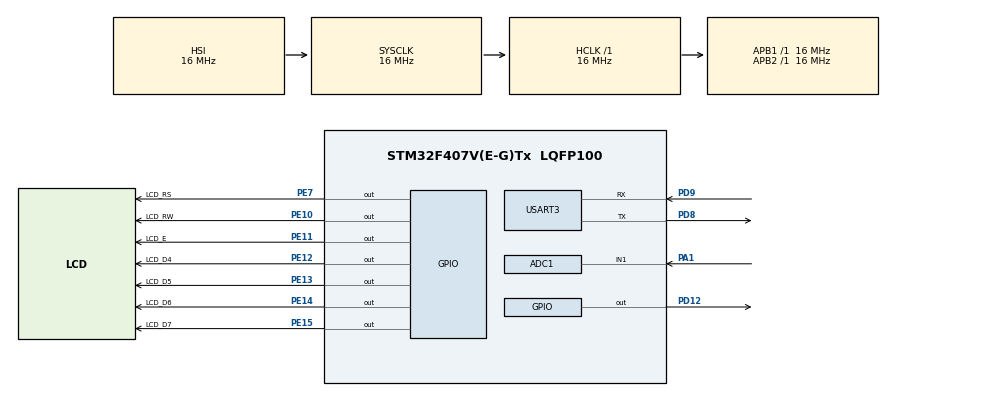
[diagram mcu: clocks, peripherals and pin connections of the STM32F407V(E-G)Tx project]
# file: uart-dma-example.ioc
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ADC1.Channel-1\#ChannelRegularConversion=ADC_CHANNEL_1
ADC1.NbrOfConversionFlag=1
ADC1.Rank-1\#ChannelRegularConversion=1
ADC1.SamplingTime-1\#ChannelRegularConversion=ADC_SAMPLETIME_3CYCLES
ADC1.master=1
Dma.Request0=USART3_RX
Dma.USART3_RX.0.Direction=DMA_PERIPH_TO_MEMORY
Dma.USART3_RX.0.FIFOMode=DMA_FIFOMODE_DISABLE
Dma.USART3_RX.0.Instance=DMA1_Stream1
Dma.USART3_RX.0.MemDataAlignment=DMA_MDATAALIGN_BYTE
Dma.USART3_RX.0.MemInc=DMA_MINC_ENABLE
Dma.USART3_RX.0.Mode=DMA_CIRCULAR
Dma.USART3_RX.0.PeriphDataAlignment=DMA_PDATAALIGN_BYTE
Dma.USART3_RX.0.PeriphInc=DMA_PINC_DISABLE
Dma.USART3_RX.0.Priority=DMA_PRIORITY_LOW
FREERTOS.Tasks01=serial_listener,24,128,serial_listen,Default,NULL,Dynamic,NULL,NULL;display_task,24,128,lcd_display,Default,NULL,Dynamic,NULL,NULL
Mcu.Family=STM32F4
Mcu.Name=STM32F407V(E-G)Tx
Mcu.Package=LQFP100
NVIC.DMA1_Stream1_IRQn=true\:5\:0\:false\:false\:true\:true\:false\:true
NVIC.PriorityGroup=NVIC_PRIORITYGROUP_4
NVIC.TIM6_DAC_IRQn=true\:15\:0\:false\:false\:true\:false\:false\:true
NVIC.TimeBase=TIM6_DAC_IRQn
NVIC.TimeBaseIP=TIM6
PA1.Signal=ADCx_IN1
PD12.Signal=GPIO_Output
PD8.Mode=Asynchronous
PD8.Signal=USART3_TX
PD9.Mode=Asynchronous
PD9.Signal=USART3_RX
PE10.GPIO_Label=LCD_RW
PE10.Signal=GPIO_Output
PE11.GPIO_Label=LCD_E
PE11.Signal=GPIO_Output
PE12.GPIO_Label=LCD_D4
PE12.Signal=GPIO_Output
PE13.GPIO_Label=LCD_D5
PE13.Signal=GPIO_Output
PE14.GPIO_Label=LCD_D6
PE14.Signal=GPIO_Output
PE15.GPIO_Label=LCD_D7
PE15.Signal=GPIO_Output
PE7.GPIO_Label=LCD_RS
PE7.Signal=GPIO_Output
ProjectManager.HeapSize=0x200
ProjectManager.StackSize=0x400
ProjectManager.TargetToolchain=STM32CubeIDE
RCC.AHBFreq_Value=16000000
RCC.APB1Freq_Value=16000000
RCC.APB2Freq_Value=16000000
RCC.CortexFreq_Value=16000000
RCC.HSE_VALUE=25000000
RCC.HSI_VALUE=16000000
RCC.LSE_VALUE=32768
RCC.SYSCLKFreq_VALUE=16000000
RCC.VCOOutputFreq_Value=192000000
SH.ADCx_IN1.0=ADC1_IN1,IN1
USART3.VirtualMode=VM_ASYNC
VP_FREERTOS_VS_CMSIS_V2.Mode=CMSIS_V2
VP_SYS_VS_tim6.Mode=TIM6
board=custom

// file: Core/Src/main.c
/* USER CODE BEGIN Header */
/**
 ******************************************************************************
 * @file           : main.c
 * @brief          : Main program body
 ******************************************************************************
 * @attention
 *
 * <h2><center>&copy; Copyright (c) 2021 STMicroelectronics.
 * All rights reserved.</center></h2>
 *
 * This software component is licensed by ST under BSD 3-Clause license,
 * the "License"; You may not use this file except in compliance with the
 * License. You may obtain a copy of the License at:
 *                        opensource.org/licenses/BSD-3-Clause
 *
 ******************************************************************************
 */
/* USER CODE END Header */
#include "main.h"
#include "cmsis_os.h"

/* USER CODE BEGIN Includes */
#include "hd44780.h"
#include "serial_listener.h"
#include "commands_manager.h"
/* USER CODE END Includes */

ADC_HandleTypeDef hadc1;

UART_HandleTypeDef huart3;
DMA_HandleTypeDef hdma_usart3_rx;

/* Definitions for serial_listener */
osThreadId_t serial_listenerHandle;
const osThreadAttr_t serial_listener_attributes = {
    .name = "serial_listener",
    .stack_size = 128 * 4,
    .priority = (osPriority_t) osPriorityNormal,
};
/* Definitions for display_task */
osThreadId_t display_taskHandle;
const osThreadAttr_t display_task_attributes = {
    .name = "display_task",
    .stack_size = 128 * 4,
    .priority = (osPriority_t) osPriorityNormal,
};

void SystemClock_Config(void);
static void MX_GPIO_Init(void);
static void MX_ADC1_Init(void);
static void MX_DMA_Init(void);
static void MX_USART3_UART_Init(void);
void serial_listen(void *argument);
void lcd_display(void *argument);

int main(void)
{

    /* MCU Configuration--------------------------------------------------------*/

    /* Reset of all peripherals, Initializes the Flash interface and the Systick. */
    HAL_Init();

    /* Configure the system clock */
    SystemClock_Config();

    /* Initialize all configured peripherals */
    MX_GPIO_Init();
    MX_ADC1_Init();
    MX_DMA_Init();
    MX_USART3_UART_Init();
    /* USER CODE BEGIN 2 */

    lcdInit();
    /* USER CODE END 2 */

    /* Init scheduler */
    osKernelInitialize();

    /* Create the thread(s) */
    /* creation of serial_listener */
    serial_listenerHandle = osThreadNew(serial_listen, NULL, &serial_listener_attributes);

    /* creation of display_task */
    display_taskHandle = osThreadNew(lcd_display, NULL, &display_task_attributes);

    /* Start scheduler */
    osKernelStart();

    /* We should never get here as control is now taken by the scheduler */
    /* Infinite loop */
    /* USER CODE BEGIN WHILE */

    //  while (1)
    //  {
    /* USER CODE END WHILE */

    /* USER CODE BEGIN 3 */
    //  }
    /* USER CODE END 3 */
}

void SystemClock_Config(void)
{
    RCC_OscInitTypeDef RCC_OscInitStruct = { 0 };
    RCC_ClkInitTypeDef RCC_ClkInitStruct = { 0 };

    /** Configure the main internal regulator output voltage
     */
    __HAL_RCC_PWR_CLK_ENABLE();
    __HAL_PWR_VOLTAGESCALING_CONFIG(PWR_REGULATOR_VOLTAGE_SCALE1);
    /** Initializes the RCC Oscillators according to the specified parameters
     * in the RCC_OscInitTypeDef structure.
     */
    RCC_OscInitStruct.OscillatorType = RCC_OSCILLATORTYPE_HSI;
    RCC_OscInitStruct.HSIState = RCC_HSI_ON;
    RCC_OscInitStruct.HSICalibrationValue = RCC_HSICALIBRATION_DEFAULT;
    RCC_OscInitStruct.PLL.PLLState = RCC_PLL_NONE;
    if (HAL_RCC_OscConfig(&RCC_OscInitStruct) != HAL_OK) {
        Error_Handler();
    }
    /** Initializes the CPU, AHB and APB buses clocks
     */
    RCC_ClkInitStruct.ClockType = RCC_CLOCKTYPE_HCLK | RCC_CLOCKTYPE_SYSCLK | RCC_CLOCKTYPE_PCLK1
            | RCC_CLOCKTYPE_PCLK2;
    RCC_ClkInitStruct.SYSCLKSource = RCC_SYSCLKSOURCE_HSI;
    RCC_ClkInitStruct.AHBCLKDivider = RCC_SYSCLK_DIV1;
    RCC_ClkInitStruct.APB1CLKDivider = RCC_HCLK_DIV1;
    RCC_ClkInitStruct.APB2CLKDivider = RCC_HCLK_DIV1;

    if (HAL_RCC_ClockConfig(&RCC_ClkInitStruct, FLASH_LATENCY_0) != HAL_OK) {
        Error_Handler();
    }
}

static void MX_ADC1_Init(void)
{

    ADC_ChannelConfTypeDef sConfig = { 0 };

    /** Configure the global features of the ADC (Clock, Resolution, Data Alignment and number of conversion)
     */
    hadc1.Instance = ADC1;
    hadc1.Init.ClockPrescaler = ADC_CLOCK_SYNC_PCLK_DIV2;
    hadc1.Init.Resolution = ADC_RESOLUTION_12B;
    hadc1.Init.ScanConvMode = DISABLE;
    hadc1.Init.ContinuousConvMode = DISABLE;
    hadc1.Init.DiscontinuousConvMode = DISABLE;
    hadc1.Init.ExternalTrigConvEdge = ADC_EXTERNALTRIGCONVEDGE_NONE;
    hadc1.Init.ExternalTrigConv = ADC_SOFTWARE_START;
    hadc1.Init.DataAlign = ADC_DATAALIGN_RIGHT;
    hadc1.Init.NbrOfConversion = 1;
    hadc1.Init.DMAContinuousRequests = DISABLE;
    hadc1.Init.EOCSelection = ADC_EOC_SINGLE_CONV;
    if (HAL_ADC_Init(&hadc1) != HAL_OK) {
        Error_Handler();
    }
    /** Configure for the selected ADC regular channel its corresponding rank in the sequencer and its sample time.
     */
    sConfig.Channel = ADC_CHANNEL_1;
    sConfig.Rank = 1;
    sConfig.SamplingTime = ADC_SAMPLETIME_3CYCLES;
    if (HAL_ADC_ConfigChannel(&hadc1, &sConfig) != HAL_OK) {
        Error_Handler();
    }

}

static void MX_USART3_UART_Init(void)
{

    huart3.Instance = USART3;
    huart3.Init.BaudRate = 115200;
    huart3.Init.WordLength = UART_WORDLENGTH_8B;
    huart3.Init.StopBits = UART_STOPBITS_1;
    huart3.Init.Parity = UART_PARITY_NONE;
    huart3.Init.Mode = UART_MODE_TX_RX;
    huart3.Init.HwFlowCtl = UART_HWCONTROL_NONE;
    huart3.Init.OverSampling = UART_OVERSAMPLING_16;
    if (HAL_UART_Init(&huart3) != HAL_OK) {
        Error_Handler();
    }

}

static void MX_DMA_Init(void)
{

    /* DMA controller clock enable */
    __HAL_RCC_DMA1_CLK_ENABLE();

    /* DMA interrupt init */
    /* DMA1_Stream1_IRQn interrupt configuration */
    HAL_NVIC_SetPriority(DMA1_Stream1_IRQn, 5, 0);
    HAL_NVIC_EnableIRQ(DMA1_Stream1_IRQn);

}

static void MX_GPIO_Init(void)
{
    GPIO_InitTypeDef GPIO_InitStruct = { 0 };

    /* GPIO Ports Clock Enable */
    __HAL_RCC_GPIOA_CLK_ENABLE();
    __HAL_RCC_GPIOE_CLK_ENABLE();
    __HAL_RCC_GPIOD_CLK_ENABLE();

    /*Configure GPIO pin Output Level */
    HAL_GPIO_WritePin(GPIOE,
            LCD_RS_Pin | LCD_RW_Pin | LCD_E_Pin | LCD_D4_Pin | LCD_D5_Pin | LCD_D6_Pin | LCD_D7_Pin,
            GPIO_PIN_RESET);

    /*Configure GPIO pin Output Level */
    HAL_GPIO_WritePin(GPIOD, GPIO_PIN_12, GPIO_PIN_RESET);

    /*Configure GPIO pins : LCD_RS_Pin LCD_RW_Pin LCD_E_Pin LCD_D4_Pin
     LCD_D5_Pin LCD_D6_Pin LCD_D7_Pin */
    GPIO_InitStruct.Pin = LCD_RS_Pin | LCD_RW_Pin | LCD_E_Pin | LCD_D4_Pin | LCD_D5_Pin | LCD_D6_Pin
            | LCD_D7_Pin;
    GPIO_InitStruct.Mode = GPIO_MODE_OUTPUT_PP;
    GPIO_InitStruct.Pull = GPIO_NOPULL;
    GPIO_InitStruct.Speed = GPIO_SPEED_FREQ_LOW;
    HAL_GPIO_Init(GPIOE, &GPIO_InitStruct);

    /*Configure GPIO pin : PD12 */
    GPIO_InitStruct.Pin = GPIO_PIN_12;
    GPIO_InitStruct.Mode = GPIO_MODE_OUTPUT_PP;
    GPIO_InitStruct.Pull = GPIO_NOPULL;
    GPIO_InitStruct.Speed = GPIO_SPEED_FREQ_LOW;
    HAL_GPIO_Init(GPIOD, &GPIO_InitStruct);

}

void serial_listen(void *argument)
{
    /* USER CODE BEGIN 5 */
    /* Infinite loop */
    serial_listener_start(process_command);
    for (;;) {

    }
    /* USER CODE END 5 */
}

void lcd_display(void *argument)
{
    /* USER CODE BEGIN lcd_display */
    /* Infinite loop */
    for (;;) {
        HAL_ADC_Start(&hadc1);
        HAL_ADC_PollForConversion(&hadc1, HAL_MAX_DELAY);
        uint8_t raw_adc_value = HAL_ADC_GetValue(&hadc1);
        lcdClrScr();
        lcdPuts("ADC value: ");
        lcdItos(raw_adc_value);
        osDelay(500);
    }
    /* USER CODE END lcd_display */
}

void HAL_TIM_PeriodElapsedCallback(TIM_HandleTypeDef *htim)
{
    if (htim->Instance == TIM6) {
        HAL_IncTick();
    }
}

void Error_Handler(void)
{
    __disable_irq();
    while (1) {
    }
}
